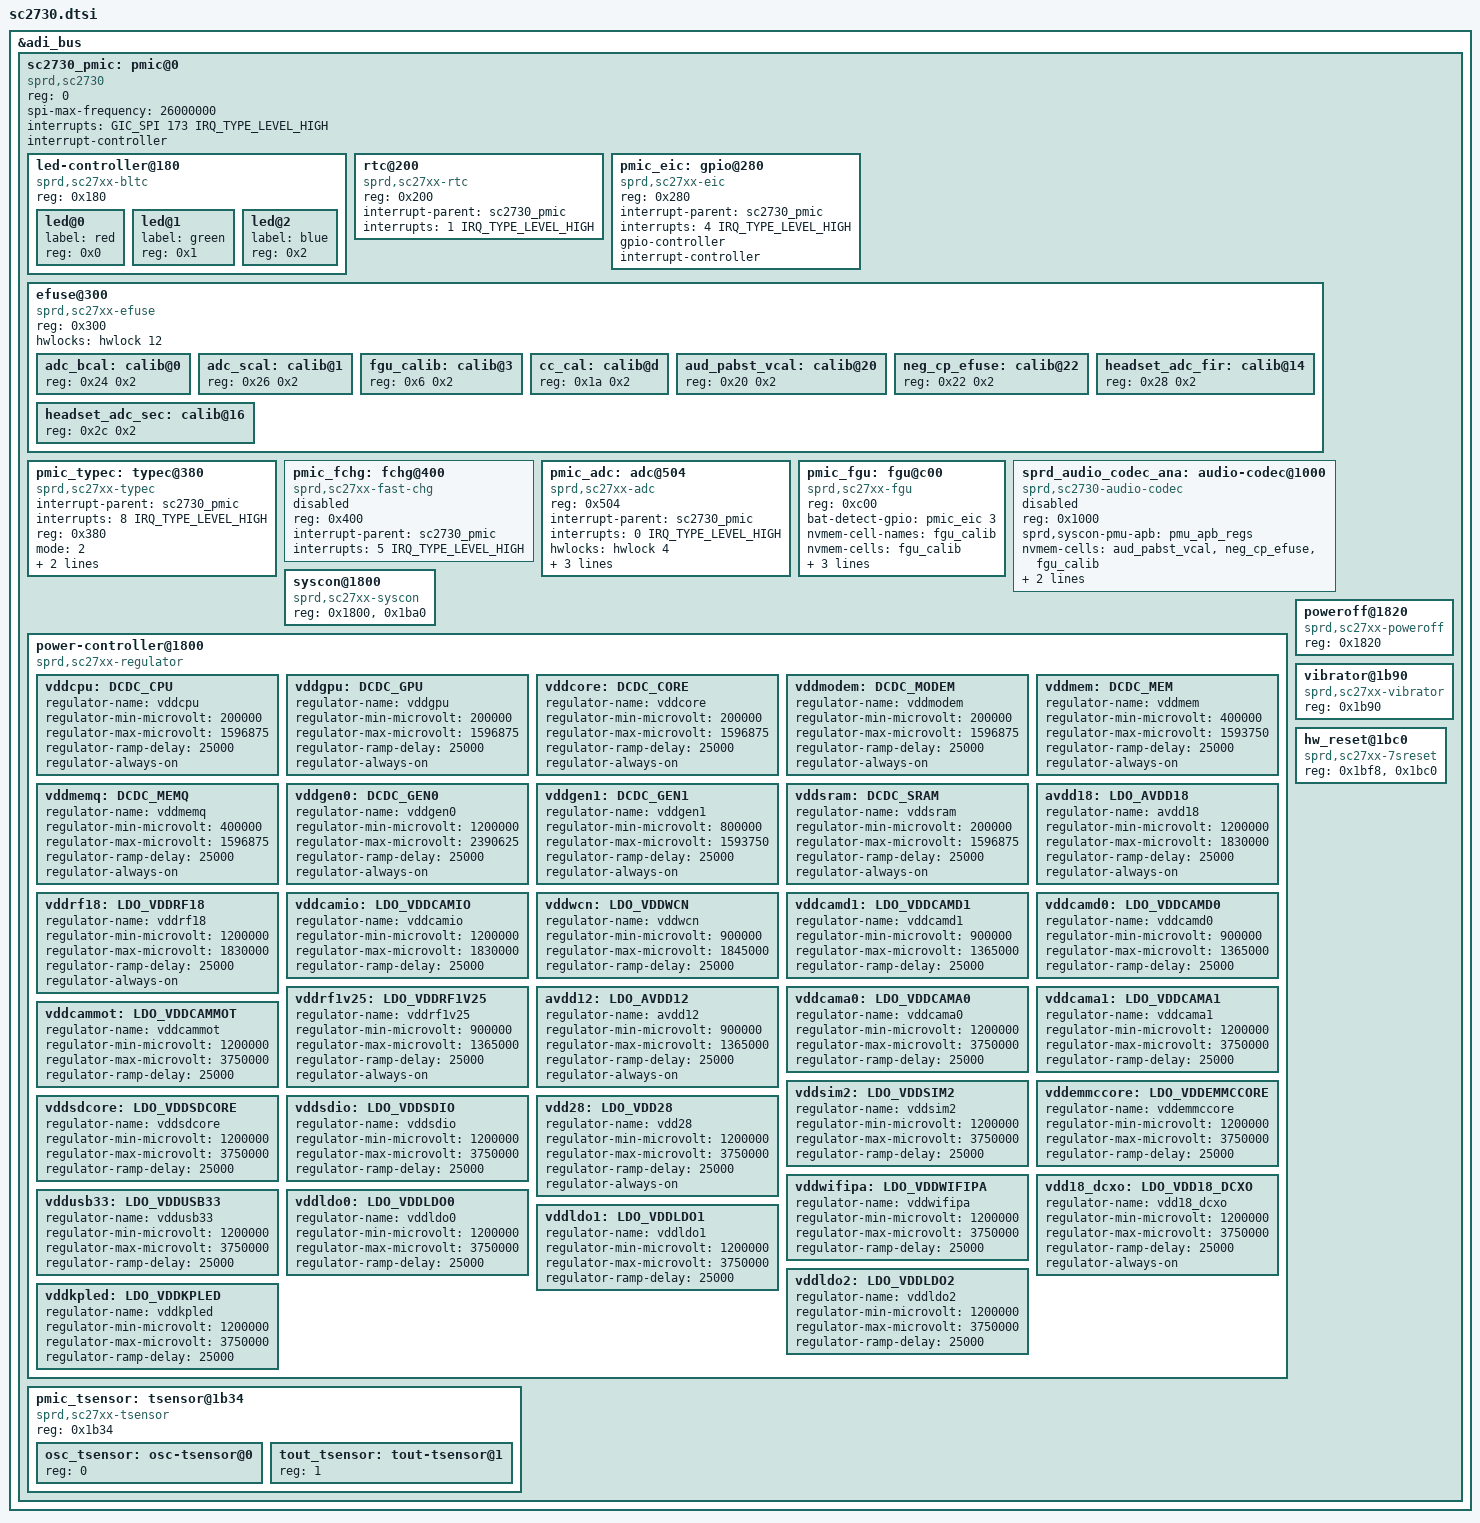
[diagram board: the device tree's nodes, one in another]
/*
 * Spreadtrum SC2730 PMIC dts file
 *
 * Copyright (C) 2018, Spreadtrum Communications Inc.
 *
 * SPDX-License-Identifier: (GPL-2.0+ OR MIT)
 */

&adi_bus {
	sc2730_pmic: pmic@0 {
		compatible = "sprd,sc2730";
		reg = <0>;
		spi-max-frequency = <26000000>;
		interrupts = <GIC_SPI 173 IRQ_TYPE_LEVEL_HIGH>;
		interrupt-controller;
		#interrupt-cells = <2>;
		#address-cells = <1>;
		#size-cells = <0>;

		led-controller@180 {
			compatible = "sprd,sc27xx-bltc", "sprd,sc2730-bltc";
			#address-cells = <1>;
			#size-cells = <0>;
			reg = <0x180>;

			led@0 {
				label = "red";
				reg = <0x0>;
			};

			led@1 {
				label = "green";
				reg = <0x1>;
			};

			led@2 {
				label = "blue";
				reg = <0x2>;
			};
		};

		rtc@200 {
			compatible = "sprd,sc27xx-rtc", "sprd,sc2730-rtc";
			reg = <0x200>;
			interrupt-parent = <&sc2730_pmic>;
			interrupts = <1 IRQ_TYPE_LEVEL_HIGH>;
		};

		pmic_eic: gpio@280 {
			compatible = "sprd,sc27xx-eic", "sprd,sc2730-eic";
			reg = <0x280>;
			interrupt-parent = <&sc2730_pmic>;
			interrupts = <4 IRQ_TYPE_LEVEL_HIGH>;
			gpio-controller;
			#gpio-cells = <2>;
			interrupt-controller;
			#interrupt-cells = <2>;
		};

		efuse@300 {
			compatible = "sprd,sc27xx-efuse", "sprd,sc2730-efuse";
			reg = <0x300>;
			#address-cells = <1>;
			#size-cells = <1>;
			hwlocks = <&hwlock 12>;
			/* Data cells */
			adc_bcal: calib@0 {
				reg = <0x24 0x2>;
			};

			adc_scal: calib@1 {
				reg = <0x26 0x2>;
			};

			fgu_calib: calib@3 {
				reg = <0x6 0x2>;
			};

			cc_cal: calib@d {
				reg = <0x1a 0x2>;
			};

			aud_pabst_vcal: calib@20 {
				reg = <0x20 0x2>;
			};

			neg_cp_efuse: calib@22 {
				reg = <0x22 0x2>;
			};

			headset_adc_fir: calib@14 {
				reg = <0x28 0x2>;
			};

			headset_adc_sec: calib@16 {
				reg = <0x2c 0x2>;
			};
		};

		pmic_typec: typec@380 {
			compatible = "sprd,sc27xx-typec", "sprd,sc2730-typec";
			interrupt-parent = <&sc2730_pmic>;
			interrupts = <8 IRQ_TYPE_LEVEL_HIGH>;
			reg = <0x380>;
			mode = <2>;
			nvmem-cells = <&cc_cal>;
			nvmem-cell-names = "cc_calib";
		};

		pmic_fchg: fchg@400 {
			compatible = "sprd,sc27xx-fast-chg", "sprd,sc2730-fast-charger";
			reg = <0x400>;
			interrupt-parent = <&sc2730_pmic>;
			interrupts = <5 IRQ_TYPE_LEVEL_HIGH>;
			status = "disabled";
		};

		pmic_adc: adc@504 {
			compatible = "sprd,sc27xx-adc", "sprd,sc2730-adc";
			reg = <0x504>;
			interrupt-parent = <&sc2730_pmic>;
			interrupts = <0 IRQ_TYPE_LEVEL_HIGH>;
			#io-channel-cells = <1>;
			hwlocks = <&hwlock 4>;
			nvmem-cells = <&adc_bcal>, <&adc_scal>;
			nvmem-cell-names = "big_scale_calib", "small_scale_calib";
		};

		pmic_fgu: fgu@c00 {
			compatible = "sprd,sc27xx-fgu", "sprd,sc2730-fgu";
			reg = <0xc00>;
			bat-detect-gpio = <&pmic_eic 3 GPIO_ACTIVE_HIGH>;
			nvmem-cell-names = "fgu_calib";
			nvmem-cells = <&fgu_calib>;
			io-channels = <&pmic_adc 0>, <&pmic_adc 14>;
			io-channel-names = "bat-temp", "charge-vol";
			interrupt-parent = <&sc2730_pmic>;
			interrupts = <3 IRQ_TYPE_LEVEL_HIGH>;
		};

		sprd_audio_codec_ana: audio-codec@1000 {
			compatible = "sprd,sc2730-audio-codec",
				"sprd,sc27xx-audio-codec";
			#sound-dai-cells = <1>;
			reg = <0x1000>;
			sprd,syscon-pmu-apb = <&pmu_apb_regs>;
			nvmem-cells = <&aud_pabst_vcal>,
				<&neg_cp_efuse>,
				<&fgu_calib>;
			nvmem-cell-names = "aud_pabst_vcal_efuse",
					"neg_cp_efuse",
					"fgu_4p2_efuse";
			status = "disabled";
		};

		syscon@1800 {
			compatible = "sprd,sc27xx-syscon";
			reg = <0x1800>, <0x1ba0>;
		};

		power-controller@1800 {
			compatible = "sprd,sc27xx-regulator", "sprd,sc2730-regulator";

			vddcpu: DCDC_CPU {
				regulator-name = "vddcpu";
				regulator-min-microvolt = <200000>;
				regulator-max-microvolt = <1596875>;
				regulator-ramp-delay = <25000>;
				regulator-always-on;
			};

			vddgpu: DCDC_GPU {
				regulator-name = "vddgpu";
				regulator-min-microvolt = <200000>;
				regulator-max-microvolt = <1596875>;
				regulator-ramp-delay = <25000>;
				regulator-always-on;
			};

			vddcore: DCDC_CORE {
				regulator-name = "vddcore";
				regulator-min-microvolt = <200000>;
				regulator-max-microvolt = <1596875>;
				regulator-ramp-delay = <25000>;
				regulator-always-on;
			};

			vddmodem: DCDC_MODEM {
				regulator-name = "vddmodem";
				regulator-min-microvolt = <200000>;
				regulator-max-microvolt = <1596875>;
				regulator-ramp-delay = <25000>;
				regulator-always-on;
			};

			vddmem: DCDC_MEM {
				regulator-name = "vddmem";
				regulator-min-microvolt = <400000>;
				regulator-max-microvolt = <1593750>;
				regulator-ramp-delay = <25000>;
				regulator-always-on;
			};

			vddmemq: DCDC_MEMQ {
				regulator-name = "vddmemq";
				regulator-min-microvolt = <400000>;
				regulator-max-microvolt = <1596875>;
				regulator-ramp-delay = <25000>;
				regulator-always-on;
			};

			vddgen0: DCDC_GEN0 {
				regulator-name = "vddgen0";
				regulator-min-microvolt = <1200000>;
				regulator-max-microvolt = <2390625>;
				regulator-ramp-delay = <25000>;
				regulator-always-on;
			};

			vddgen1: DCDC_GEN1 {
				regulator-name = "vddgen1";
				regulator-min-microvolt = <800000>;
				regulator-max-microvolt = <1593750>;
				regulator-ramp-delay = <25000>;
				regulator-always-on;
			};

			vddsram: DCDC_SRAM {
				regulator-name = "vddsram";
				regulator-min-microvolt = <200000>;
				regulator-max-microvolt = <1596875>;
				regulator-ramp-delay = <25000>;
				regulator-always-on;
			};

			avdd18: LDO_AVDD18 {
				regulator-name = "avdd18";
				regulator-min-microvolt = <1200000>;
				regulator-max-microvolt = <1830000>;
				regulator-ramp-delay = <25000>;
				regulator-always-on;
			};

			vddrf18: LDO_VDDRF18 {
				regulator-name = "vddrf18";
				regulator-min-microvolt = <1200000>;
				regulator-max-microvolt = <1830000>;
				regulator-ramp-delay = <25000>;
				regulator-always-on;
			};

			vddcamio: LDO_VDDCAMIO {
				regulator-name = "vddcamio";
				regulator-min-microvolt = <1200000>;
				regulator-max-microvolt = <1830000>;
				regulator-ramp-delay = <25000>;
			};

			vddwcn: LDO_VDDWCN {
				regulator-name = "vddwcn";
				regulator-min-microvolt = <900000>;
				regulator-max-microvolt = <1845000>;
				regulator-ramp-delay = <25000>;
			};

			vddcamd1: LDO_VDDCAMD1 {
				regulator-name = "vddcamd1";
				regulator-min-microvolt = <900000>;
				regulator-max-microvolt = <1365000>;
				regulator-ramp-delay = <25000>;
			};

			vddcamd0: LDO_VDDCAMD0 {
				regulator-name = "vddcamd0";
				regulator-min-microvolt = <900000>;
				regulator-max-microvolt = <1365000>;
				regulator-ramp-delay = <25000>;
			};

			vddrf1v25: LDO_VDDRF1V25 {
				regulator-name = "vddrf1v25";
				regulator-min-microvolt = <900000>;
				regulator-max-microvolt = <1365000>;
				regulator-ramp-delay = <25000>;
				regulator-always-on;
			};

			avdd12: LDO_AVDD12 {
				regulator-name = "avdd12";
				regulator-min-microvolt = <900000>;
				regulator-max-microvolt = <1365000>;
				regulator-ramp-delay = <25000>;
				regulator-always-on;
			};

			vddcama0: LDO_VDDCAMA0 {
				regulator-name = "vddcama0";
				regulator-min-microvolt = <1200000>;
				regulator-max-microvolt = <3750000>;
				regulator-ramp-delay = <25000>;
			};

			vddcama1: LDO_VDDCAMA1 {
				regulator-name = "vddcama1";
				regulator-min-microvolt = <1200000>;
				regulator-max-microvolt = <3750000>;
				regulator-ramp-delay = <25000>;
			};

			vddcammot: LDO_VDDCAMMOT {
				regulator-name = "vddcammot";
				regulator-min-microvolt = <1200000>;
				regulator-max-microvolt = <3750000>;
				regulator-ramp-delay = <25000>;
			};

			vddsim2: LDO_VDDSIM2 {
				regulator-name = "vddsim2";
				regulator-min-microvolt = <1200000>;
				regulator-max-microvolt = <3750000>;
				regulator-ramp-delay = <25000>;
			};

			vddemmccore: LDO_VDDEMMCCORE {
				regulator-name = "vddemmccore";
				regulator-min-microvolt = <1200000>;
				regulator-max-microvolt = <3750000>;
				regulator-ramp-delay = <25000>;
			};

			vddsdcore: LDO_VDDSDCORE {
				regulator-name = "vddsdcore";
				regulator-min-microvolt = <1200000>;
				regulator-max-microvolt = <3750000>;
				regulator-ramp-delay = <25000>;
			};

			vddsdio: LDO_VDDSDIO {
				regulator-name = "vddsdio";
				regulator-min-microvolt = <1200000>;
				regulator-max-microvolt = <3750000>;
				regulator-ramp-delay = <25000>;
			};

			vdd28: LDO_VDD28 {
				regulator-name = "vdd28";
				regulator-min-microvolt = <1200000>;
				regulator-max-microvolt = <3750000>;
				regulator-ramp-delay = <25000>;
				regulator-always-on;
			};

			vddwifipa: LDO_VDDWIFIPA {
				regulator-name = "vddwifipa";
				regulator-min-microvolt = <1200000>;
				regulator-max-microvolt = <3750000>;
				regulator-ramp-delay = <25000>;
			};

			vdd18_dcxo: LDO_VDD18_DCXO {
				regulator-name = "vdd18_dcxo";
				regulator-min-microvolt = <1200000>;
				regulator-max-microvolt = <3750000>;
				regulator-ramp-delay = <25000>;
				regulator-always-on;
			};

			vddusb33: LDO_VDDUSB33 {
				regulator-name = "vddusb33";
				regulator-min-microvolt = <1200000>;
				regulator-max-microvolt = <3750000>;
				regulator-ramp-delay = <25000>;
			};

			vddldo0: LDO_VDDLDO0 {
				regulator-name = "vddldo0";
				regulator-min-microvolt = <1200000>;
				regulator-max-microvolt = <3750000>;
				regulator-ramp-delay = <25000>;
			};

			vddldo1: LDO_VDDLDO1 {
				regulator-name = "vddldo1";
				regulator-min-microvolt = <1200000>;
				regulator-max-microvolt = <3750000>;
				regulator-ramp-delay = <25000>;
			};

			vddldo2: LDO_VDDLDO2 {
				regulator-name = "vddldo2";
				regulator-min-microvolt = <1200000>;
				regulator-max-microvolt = <3750000>;
				regulator-ramp-delay = <25000>;
			};

			vddkpled: LDO_VDDKPLED {
				regulator-name = "vddkpled";
				regulator-min-microvolt = <1200000>;
				regulator-max-microvolt = <3750000>;
				regulator-ramp-delay = <25000>;
			};
		};

		poweroff@1820 {
			compatible = "sprd,sc27xx-poweroff", "sprd,sc2730-poweroff";
			reg = <0x1820>;
		};

		pmic_tsensor: tsensor@1b34 {
			compatible = "sprd,sc27xx-tsensor", "sprd,sc2730-tsensor";
			#thermal-sensor-cells = <1>;
			reg = <0x1b34>;

			osc_tsensor: osc-tsensor@0{
				reg = <0>;
			};

			tout_tsensor: tout-tsensor@1{
				reg = <1>;
			};
		};

		vibrator@1b90 {
			compatible = "sprd,sc27xx-vibrator", "sprd,sc2730-vibrator";
			reg = <0x1b90>;
		};

		hw_reset@1bc0 {
			compatible = "sprd,sc27xx-7sreset", "sprd,sc2730-7sreset";
			reg = <0x1bf8>, <0x1bc0>;
		};
	};
};
